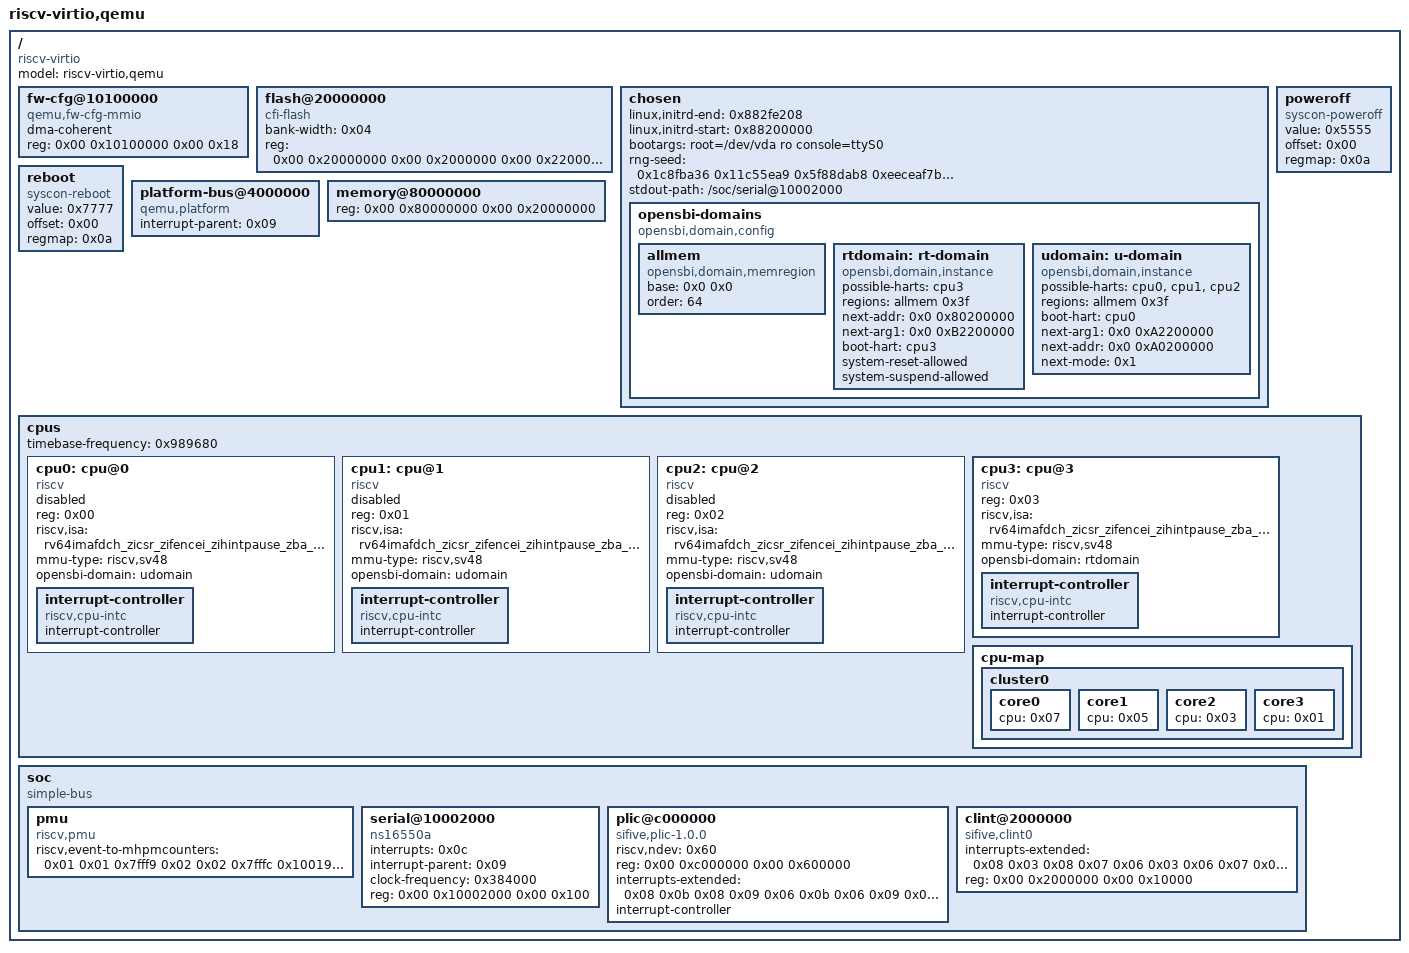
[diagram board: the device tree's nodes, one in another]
/dts-v1/;

/ {
	#address-cells = <0x02>;
	#size-cells = <0x02>;
	compatible = "riscv-virtio";
	model = "riscv-virtio,qemu";

	fw-cfg@10100000 {
		dma-coherent;
		reg = <0x00 0x10100000 0x00 0x18>;
		compatible = "qemu,fw-cfg-mmio";
	};

	flash@20000000 {
		bank-width = <0x04>;
		reg = <0x00 0x20000000 0x00 0x2000000 0x00 0x22000000 0x00 0x2000000>;
		compatible = "cfi-flash";
	};

	chosen {
		linux,initrd-end = <0x882fe208>;
		linux,initrd-start = <0x88200000>;
		bootargs = "root=/dev/vda ro console=ttyS0";
		rng-seed = <0x1c8fba36 0x11c55ea9 0x5f88dab8 0xeeceaf7b 0x57d0ac47 0xf075ac8a 0x89db86a2 0x9cba55d>;
		stdout-path = "/soc/serial@10002000";
		opensbi-domains {
			compatible = "opensbi,domain,config";
			allmem: allmem {
				compatible = "opensbi,domain,memregion";
				base = <0x0 0x0>;
				order = <64>;
			};

			rtdomain: rt-domain {
				compatible = "opensbi,domain,instance";
				possible-harts = <&cpu3>;
				regions = <&allmem 0x3f>;
				next-addr = <0x0 0x80200000>;
				next-arg1 = <0x0 0xB2200000>;
				boot-hart = <&cpu3>;
				system-reset-allowed;
				system-suspend-allowed;
			};

			udomain: u-domain {
				compatible = "opensbi,domain,instance";
				possible-harts = <&cpu0 &cpu1 &cpu2>;
				regions = <&allmem 0x3f>;
				boot-hart = <&cpu0>;
				next-arg1 = <0x0 0xA2200000>;
				next-addr = <0x0 0xA0200000>;
				next-mode = <0x1>;
			};
		};
	};

	poweroff {
		value = <0x5555>;
		offset = <0x00>;
		regmap = <0x0a>;
		compatible = "syscon-poweroff";
	};

	reboot {
		value = <0x7777>;
		offset = <0x00>;
		regmap = <0x0a>;
		compatible = "syscon-reboot";
	};

	platform-bus@4000000 {
		interrupt-parent = <0x09>;
		ranges = <0x00 0x00 0x4000000 0x2000000>;
		#address-cells = <0x01>;
		#size-cells = <0x01>;
		compatible = "qemu,platform\0simple-bus";
	};

	memory@80000000 {
		device_type = "memory";
		reg = <0x00 0x80000000 0x00 0x20000000>;
	};

	cpus {
		#address-cells = <0x01>;
		#size-cells = <0x00>;
		timebase-frequency = <0x989680>;

		cpu0:cpu@0 {
			phandle = <0x07>;
			device_type = "cpu";
			reg = <0x00>;
			status = "disabled";
			compatible = "riscv";
			riscv,isa = "rv64imafdch_zicsr_zifencei_zihintpause_zba_zbb_zbc_zbs_sstc";
			mmu-type = "riscv,sv48";
			opensbi-domain = <&udomain>;
			interrupt-controller {
				#interrupt-cells = <0x01>;
				interrupt-controller;
				compatible = "riscv,cpu-intc";
				phandle = <0x08>;
			};
		};

		cpu1:cpu@1 {
			phandle = <0x05>;
			device_type = "cpu";
			reg = <0x01>;
			status = "disabled";
			compatible = "riscv";
			riscv,isa = "rv64imafdch_zicsr_zifencei_zihintpause_zba_zbb_zbc_zbs_sstc";
			mmu-type = "riscv,sv48";
			opensbi-domain = <&udomain>;
			interrupt-controller {
				#interrupt-cells = <0x01>;
				interrupt-controller;
				compatible = "riscv,cpu-intc";
				phandle = <0x06>;
			};
		};

		cpu2:cpu@2 {
			phandle = <0x03>;
			device_type = "cpu";
			reg = <0x02>;
			status = "disabled";
			compatible = "riscv";
			riscv,isa = "rv64imafdch_zicsr_zifencei_zihintpause_zba_zbb_zbc_zbs_sstc";
			mmu-type = "riscv,sv48";
			opensbi-domain = <&udomain>;
			interrupt-controller {
				#interrupt-cells = <0x01>;
				interrupt-controller;
				compatible = "riscv,cpu-intc";
				phandle = <0x04>;
			};
		};

		cpu3:cpu@3 {
			phandle = <0x01>;
			device_type = "cpu";
			reg = <0x03>;
			status = "okay";
			compatible = "riscv";
			riscv,isa = "rv64imafdch_zicsr_zifencei_zihintpause_zba_zbb_zbc_zbs_sstc";
			mmu-type = "riscv,sv48";
			opensbi-domain = <&rtdomain>;
			interrupt-controller {
				#interrupt-cells = <0x01>;
				interrupt-controller;
				compatible = "riscv,cpu-intc";
				phandle = <0x02>;
			};
		};

		cpu-map {

			cluster0 {

				core0 {
					cpu = <0x07>;
				};

				core1 {
					cpu = <0x05>;
				};

				core2 {
					cpu = <0x03>;
				};

				core3 {
					cpu = <0x01>;
				};
			};
		};
	};

	soc {
		#address-cells = <0x02>;
		#size-cells = <0x02>;
		compatible = "simple-bus";
		ranges;

		pmu {
			riscv,event-to-mhpmcounters = <0x01 0x01 0x7fff9 0x02 0x02 0x7fffc 0x10019 0x10019 0x7fff8 0x1001b 0x1001b 0x7fff8 0x10021 0x10021 0x7fff8 0x00 0x00 0x00 0x00 0x00>;
			compatible = "riscv,pmu";
		};
		serial@10002000 {
			interrupts = <0x0c>;
			interrupt-parent = <0x09>;
			clock-frequency = <0x384000>;
			reg = <0x00 0x10002000 0x00 0x100>;
			compatible = "ns16550a";
		};
		plic@c000000 {
			phandle = <0x09>;
			riscv,ndev = <0x60>;
			reg = <0x00 0xc000000 0x00 0x600000>;
			interrupts-extended = <0x08 0x0b 0x08 0x09 0x06 0x0b 0x06 0x09 0x04 0x0b 0x04 0x09 0x02 0x0b 0x02 0x09>;
			interrupt-controller;
			compatible = "sifive,plic-1.0.0\0riscv,plic0";
			#address-cells = <0x00>;
			#interrupt-cells = <0x01>;
		};

		clint@2000000 {
			interrupts-extended = <0x08 0x03 0x08 0x07 0x06 0x03 0x06 0x07 0x04 0x03 0x04 0x07 0x02 0x03 0x02 0x07>;
			reg = <0x00 0x2000000 0x00 0x10000>;
			compatible = "sifive,clint0\0riscv,clint0";
		};
	};
};
